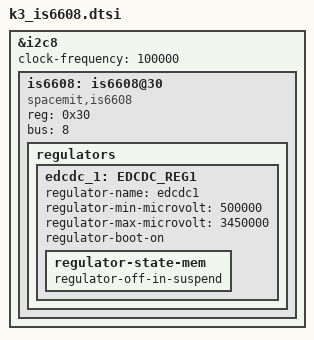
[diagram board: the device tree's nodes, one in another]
// SPDX-License-Identifier: (GPL-2.0 OR MIT)
/* Copyright (c) 2023 Spacemit, Inc */

&i2c8 {
	clock-frequency = <100000>;
	u-boot,dm-spl;
	status = "okay";

	is6608: is6608@30 {
		compatible = "spacemit,is6608";
		reg = <0x30>;
		bus = <8>;
		u-boot,dm-spl;

		regulators {
			u-boot,dm-spl;

			edcdc_1: EDCDC_REG1 {
				regulator-name = "edcdc1";
				regulator-min-microvolt = <500000>;
				regulator-max-microvolt = <3450000>;
				/* regulator-init-microvolt = <1050000>; */
				regulator-boot-on;
				u-boot,dm-spl;
				regulator-state-mem {
					regulator-off-in-suspend;
				};
			};
		};
	};
};
